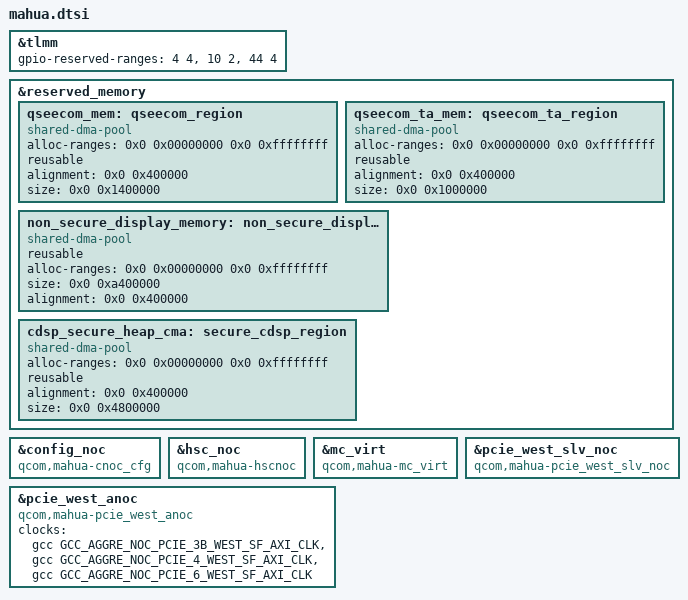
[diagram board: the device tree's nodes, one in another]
// SPDX-License-Identifier: BSD-3-Clause
/*
 * Copyright (c) Qualcomm Technologies, Inc. and/or its subsidiaries.
 */

/* Mahua is heavily based on Glymur, with some meaningful differences */

#include "glymur.dtsi"
#include "mahua-dma-heaps.dtsi"
#include "mahua-reserved-memory.dtsi"

/delete-node/ &cluster2_pd;
/delete-node/ &cpu_map_cluster2;
/delete-node/ &cpu12;
/delete-node/ &cpu13;
/delete-node/ &cpu14;
/delete-node/ &cpu15;
/delete-node/ &cpu16;
/delete-node/ &cpu17;
/delete-node/ &cpu_pd12;
/delete-node/ &cpu_pd13;
/delete-node/ &cpu_pd14;
/delete-node/ &cpu_pd15;
/delete-node/ &cpu_pd16;
/delete-node/ &cpu_pd17;

&tlmm {
	gpio-reserved-ranges = <4 4>, /* EC TZ Secure I3C */
			       <10 2>, /* OOB UART */
			       <44 4>; /* Security SPI (TPM) */
};

&reserved_memory {
		qseecom_mem: qseecom_region {
			compatible = "shared-dma-pool";
			alloc-ranges = <0x0 0x00000000 0x0 0xffffffff>;
			reusable;
			alignment = <0x0 0x400000>;
			size = <0x0 0x1400000>;
		};

		qseecom_ta_mem: qseecom_ta_region {
			compatible = "shared-dma-pool";
			alloc-ranges = <0x0 0x00000000 0x0 0xffffffff>;
			reusable;
			alignment = <0x0 0x400000>;
			size = <0x0 0x1000000>;
		};

		non_secure_display_memory: non_secure_display_region {
			compatible = "shared-dma-pool";
			reusable;
			alloc-ranges = <0x0 0x00000000 0x0 0xffffffff>;
			size = <0x0 0xa400000>;
			alignment = <0x0 0x400000>;
		};

		cdsp_secure_heap_cma: secure_cdsp_region { /* Secure DSP */
			compatible = "shared-dma-pool";
			alloc-ranges = <0x0 0x00000000 0x0 0xffffffff>;
			reusable;
			alignment = <0x0 0x400000>;
			size = <0x0 0x4800000>;
		};
};

&config_noc {
	compatible = "qcom,mahua-cnoc_cfg";
};

&hsc_noc {
	compatible = "qcom,mahua-hscnoc";
};

&mc_virt {
	compatible = "qcom,mahua-mc_virt";
};

&pcie_west_anoc {
	compatible = "qcom,mahua-pcie_west_anoc";
	clocks = <&gcc GCC_AGGRE_NOC_PCIE_3B_WEST_SF_AXI_CLK>,
		 <&gcc GCC_AGGRE_NOC_PCIE_4_WEST_SF_AXI_CLK>,
		 <&gcc GCC_AGGRE_NOC_PCIE_6_WEST_SF_AXI_CLK>;
};

&pcie_west_slv_noc {
	compatible = "qcom,mahua-pcie_west_slv_noc";
};
